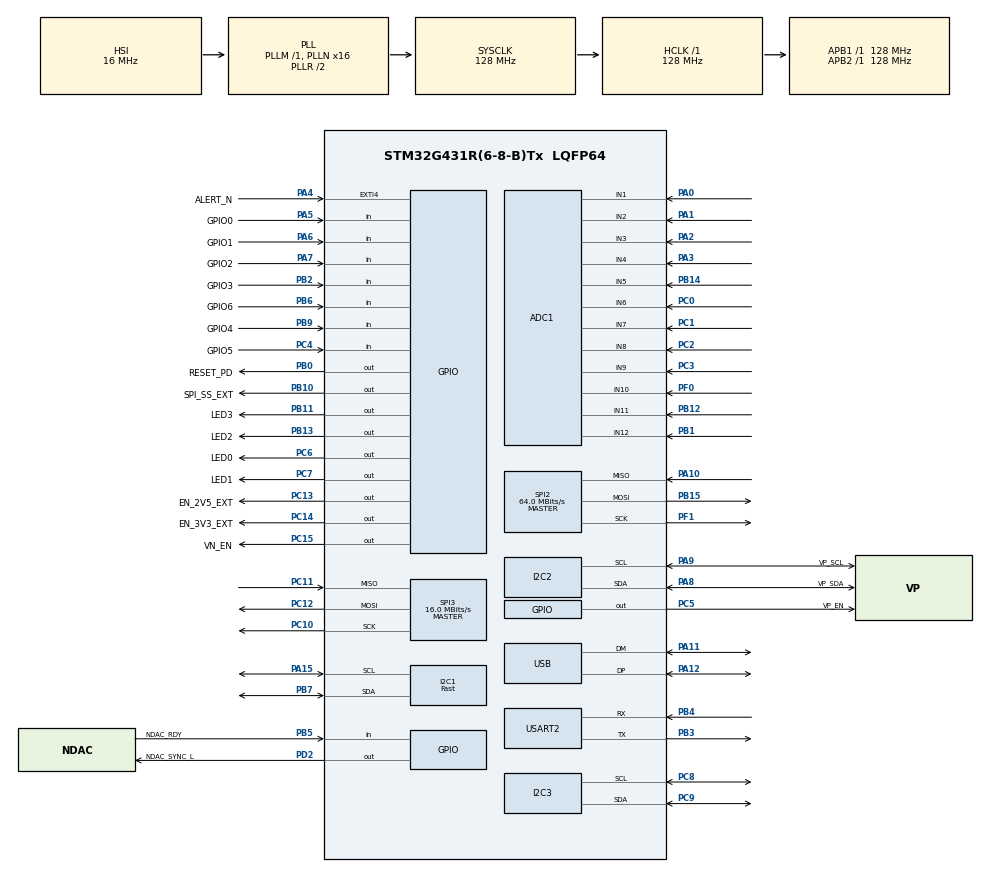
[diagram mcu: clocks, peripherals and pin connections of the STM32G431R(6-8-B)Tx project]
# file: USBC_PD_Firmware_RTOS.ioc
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ADC1.Channel-0\#ChannelRegularConversion=ADC_CHANNEL_1
ADC1.Channel-1\#ChannelRegularConversion=ADC_CHANNEL_2
ADC1.Channel-10\#ChannelRegularConversion=ADC_CHANNEL_12
ADC1.Channel-2\#ChannelRegularConversion=ADC_CHANNEL_4
ADC1.Channel-3\#ChannelRegularConversion=ADC_CHANNEL_5
ADC1.Channel-4\#ChannelRegularConversion=ADC_CHANNEL_6
ADC1.Channel-5\#ChannelRegularConversion=ADC_CHANNEL_7
ADC1.Channel-6\#ChannelRegularConversion=ADC_CHANNEL_8
ADC1.Channel-7\#ChannelRegularConversion=ADC_CHANNEL_9
ADC1.Channel-8\#ChannelRegularConversion=ADC_CHANNEL_10
ADC1.Channel-9\#ChannelRegularConversion=ADC_CHANNEL_11
ADC1.ContinuousConvMode=ENABLE
ADC1.DMAContinuousRequests=ENABLE
ADC1.NbrOfConversion=11
ADC1.NbrOfConversionFlag=1
ADC1.OffsetNumber-0\#ChannelRegularConversion=ADC_OFFSET_NONE
ADC1.OffsetNumber-1\#ChannelRegularConversion=ADC_OFFSET_NONE
ADC1.OffsetNumber-10\#ChannelRegularConversion=ADC_OFFSET_NONE
ADC1.OffsetNumber-2\#ChannelRegularConversion=ADC_OFFSET_NONE
ADC1.OffsetNumber-3\#ChannelRegularConversion=ADC_OFFSET_NONE
ADC1.OffsetNumber-4\#ChannelRegularConversion=ADC_OFFSET_NONE
ADC1.OffsetNumber-5\#ChannelRegularConversion=ADC_OFFSET_NONE
ADC1.OffsetNumber-6\#ChannelRegularConversion=ADC_OFFSET_NONE
ADC1.OffsetNumber-7\#ChannelRegularConversion=ADC_OFFSET_NONE
ADC1.OffsetNumber-8\#ChannelRegularConversion=ADC_OFFSET_NONE
ADC1.OffsetNumber-9\#ChannelRegularConversion=ADC_OFFSET_NONE
ADC1.OversamplingMode=DISABLE
ADC1.Rank-0\#ChannelRegularConversion=1
ADC1.Rank-1\#ChannelRegularConversion=2
ADC1.Rank-10\#ChannelRegularConversion=11
ADC1.Rank-2\#ChannelRegularConversion=3
ADC1.Rank-3\#ChannelRegularConversion=4
ADC1.Rank-4\#ChannelRegularConversion=5
ADC1.Rank-5\#ChannelRegularConversion=6
ADC1.Rank-6\#ChannelRegularConversion=7
ADC1.Rank-7\#ChannelRegularConversion=8
ADC1.Rank-8\#ChannelRegularConversion=9
ADC1.Rank-9\#ChannelRegularConversion=10
ADC1.SamplingTime-0\#ChannelRegularConversion=ADC_SAMPLETIME_12CYCLES_5
ADC1.SamplingTime-1\#ChannelRegularConversion=ADC_SAMPLETIME_12CYCLES_5
ADC1.SamplingTime-10\#ChannelRegularConversion=ADC_SAMPLETIME_12CYCLES_5
ADC1.SamplingTime-2\#ChannelRegularConversion=ADC_SAMPLETIME_12CYCLES_5
ADC1.SamplingTime-3\#ChannelRegularConversion=ADC_SAMPLETIME_12CYCLES_5
ADC1.SamplingTime-4\#ChannelRegularConversion=ADC_SAMPLETIME_12CYCLES_5
ADC1.SamplingTime-5\#ChannelRegularConversion=ADC_SAMPLETIME_12CYCLES_5
ADC1.SamplingTime-6\#ChannelRegularConversion=ADC_SAMPLETIME_12CYCLES_5
ADC1.SamplingTime-7\#ChannelRegularConversion=ADC_SAMPLETIME_12CYCLES_5
ADC1.SamplingTime-8\#ChannelRegularConversion=ADC_SAMPLETIME_12CYCLES_5
ADC1.SamplingTime-9\#ChannelRegularConversion=ADC_SAMPLETIME_12CYCLES_5
ADC1.master=1
Dma.ADC1.0.Direction=DMA_PERIPH_TO_MEMORY
Dma.ADC1.0.EventEnable=DISABLE
Dma.ADC1.0.Instance=DMA1_Channel1
Dma.ADC1.0.MemDataAlignment=DMA_MDATAALIGN_HALFWORD
Dma.ADC1.0.MemInc=DMA_MINC_ENABLE
Dma.ADC1.0.Mode=DMA_CIRCULAR
Dma.ADC1.0.PeriphDataAlignment=DMA_PDATAALIGN_HALFWORD
Dma.ADC1.0.PeriphInc=DMA_PINC_DISABLE
Dma.ADC1.0.Polarity=HAL_DMAMUX_REQ_GEN_RISING
Dma.ADC1.0.Priority=DMA_PRIORITY_LOW
Dma.ADC1.0.RequestNumber=1
Dma.ADC1.0.SignalID=NONE
Dma.ADC1.0.SyncEnable=DISABLE
Dma.ADC1.0.SyncPolarity=HAL_DMAMUX_SYNC_NO_EVENT
Dma.ADC1.0.SyncRequestNumber=1
Dma.ADC1.0.SyncSignalID=NONE
Dma.Request0=ADC1
FREERTOS.Queues01=serialDataQueue,12,uint32_t,0,Dynamic,NULL,NULL
FREERTOS.Tasks01=mainSystemTask,24,128,StartDefaultTask,Default,NULL,Dynamic,NULL,NULL;ledStatusTask,22,128,StartBlinkyTask,Default,NULL,Dynamic,NULL,NULL;usbCommandTask,24,128,StartusbCommandTask,Default,NULL,Dynamic,NULL,NULL;vMeasureTask,23,128,StartvMeasureTask,Default,NULL,Dynamic,NULL,NULL;iMeasureTask,23,128,StartiMeasureTask,Default,NULL,Dynamic,NULL,NULL;cmdResponseTask,25,512,StartResponseTask,Default,NULL,Dynamic,NULL,NULL
FREERTOS.configENABLE_FPU=0
FREERTOS.configTOTAL_HEAP_SIZE=8192
I2C1.I2C_Speed_Mode=I2C_Fast
I2C1.Timing=0x2040184B
I2C2.Timing=0x20A0C4DF
I2C3.Timing=0x20A0C4DF
Mcu.Family=STM32G4
Mcu.Name=STM32G431R(6-8-B)Tx
Mcu.Package=LQFP64
NVIC.DMA1_Channel1_IRQn=true\:5\:0\:false\:false\:true\:true\:false\:true\:true
NVIC.I2C1_EV_IRQn=true\:5\:0\:false\:false\:true\:true\:true\:true\:true
NVIC.PriorityGroup=NVIC_PRIORITYGROUP_4
NVIC.TIM6_DAC_IRQn=true\:15\:0\:false\:false\:true\:false\:false\:true\:true
NVIC.TimeBase=TIM6_DAC_IRQn
NVIC.TimeBaseIP=TIM6
NVIC.USART2_IRQn=true\:5\:0\:false\:false\:true\:true\:true\:true\:true
NVIC.USB_LP_IRQn=true\:5\:0\:false\:false\:true\:true\:false\:true\:true
PA0.Mode=IN1-Single-Ended
PA0.Signal=ADC1_IN1
PA1.Mode=IN2-Single-Ended
PA1.Signal=ADC1_IN2
PA10.Mode=Full_Duplex_Master
PA10.Signal=SPI2_MISO
PA11.Mode=Device
PA11.Signal=USB_DM
PA12.Mode=Device
PA12.Signal=USB_DP
PA13.Mode=Serial_Wire
PA13.Signal=SYS_JTMS-SWDIO
PA14.Mode=Serial_Wire
PA14.Signal=SYS_JTCK-SWCLK
PA15.Mode=I2C
PA15.Signal=I2C1_SCL
PA2.Mode=IN3-Single-Ended
PA2.Signal=ADC1_IN3
PA3.Mode=IN4-Single-Ended
PA3.Signal=ADC1_IN4
PA4.GPIO_Label=ALERT_N
PA4.GPIO_ModeDefaultEXTI=GPIO_MODE_IT_FALLING
PA4.Signal=GPXTI4
PA5.GPIO_Label=GPIO0
PA5.Signal=GPIO_Input
PA6.GPIO_Label=GPIO1
PA6.Signal=GPIO_Input
PA7.GPIO_Label=GPIO2
PA7.Signal=GPIO_Input
PA8.GPIO_Label=VP_SDA
PA8.Mode=I2C
PA8.Signal=I2C2_SDA
PA9.GPIO_Label=VP_SCL
PA9.Mode=I2C
PA9.Signal=I2C2_SCL
PB0.GPIO_Label=RESET_PD
PB0.Signal=GPIO_Output
PB1.Mode=IN12-Single-Ended
PB1.Signal=ADC1_IN12
PB10.GPIO_Label=SPI_SS_EXT
PB10.Signal=GPIO_Output
PB11.GPIO_Label=LED3
PB11.PinState=GPIO_PIN_SET
PB11.Signal=GPIO_Output
PB12.Mode=IN11-Single-Ended
PB12.Signal=ADC1_IN11
PB13.GPIO_Label=LED2
PB13.PinState=GPIO_PIN_SET
PB13.Signal=GPIO_Output
PB14.Mode=IN5-Single-Ended
PB14.Signal=ADC1_IN5
PB15.Mode=Full_Duplex_Master
PB15.Signal=SPI2_MOSI
PB2.GPIO_Label=GPIO3
PB2.Signal=GPIO_Input
PB3.Mode=Asynchronous
PB3.Signal=USART2_TX
PB4.Mode=Asynchronous
PB4.Signal=USART2_RX
PB5.GPIO_Label=NDAC_RDY
PB5.Signal=GPIO_Input
PB6.GPIO_Label=GPIO6
PB6.Signal=GPIO_Input
PB7.Mode=I2C
PB7.Signal=I2C1_SDA
PB9.GPIO_Label=GPIO4
PB9.Signal=GPIO_Input
PC0.Mode=IN6-Single-Ended
PC0.Signal=ADC1_IN6
PC1.Mode=IN7-Single-Ended
PC1.Signal=ADC1_IN7
PC10.Mode=Full_Duplex_Master
PC10.Signal=SPI3_SCK
PC11.Mode=Full_Duplex_Master
PC11.Signal=SPI3_MISO
PC12.Mode=Full_Duplex_Master
PC12.Signal=SPI3_MOSI
PC13.GPIO_Label=EN_2V5_EXT
PC13.GPIO_ModeDefaultOutputPP=GPIO_MODE_OUTPUT_OD
PC13.GPIO_PuPd=GPIO_NOPULL
PC13.PinState=GPIO_PIN_SET
PC13.Signal=GPIO_Output
PC14-OSC32_IN.GPIO_Label=EN_3V3_EXT
PC14-OSC32_IN.GPIO_ModeDefaultOutputPP=GPIO_MODE_OUTPUT_OD
PC14-OSC32_IN.GPIO_PuPd=GPIO_NOPULL
PC14-OSC32_IN.PinState=GPIO_PIN_SET
PC14-OSC32_IN.Signal=GPIO_Output
PC15-OSC32_OUT.GPIO_Label=VN_EN
PC15-OSC32_OUT.Signal=GPIO_Output
PC2.Mode=IN8-Single-Ended
PC2.Signal=ADC1_IN8
PC3.Mode=IN9-Single-Ended
PC3.Signal=ADC1_IN9
PC4.GPIO_Label=GPIO5
PC4.Signal=GPIO_Input
PC5.GPIO_Label=VP_EN
PC5.Signal=GPIO_Output
PC6.GPIO_Label=LED0
PC6.PinState=GPIO_PIN_SET
PC6.Signal=GPIO_Output
PC7.GPIO_Label=LED1
PC7.PinState=GPIO_PIN_SET
PC7.Signal=GPIO_Output
PC8.Mode=I2C
PC8.Signal=I2C3_SCL
PC9.Mode=I2C
PC9.Signal=I2C3_SDA
PD2.GPIO_Label=NDAC_SYNC_L
PD2.PinState=GPIO_PIN_SET
PD2.Signal=GPIO_Output
PF0-OSC_IN.Mode=IN10-Single-Ended
PF0-OSC_IN.Signal=ADC1_IN10
PF1-OSC_OUT.Mode=Full_Duplex_Master
PF1-OSC_OUT.Signal=SPI2_SCK
ProjectManager.HeapSize=0x200
ProjectManager.StackSize=0x400
ProjectManager.TargetToolchain=STM32CubeIDE
RCC.ADC12Freq_Value=128000000
RCC.AHBFreq_Value=128000000
RCC.APB1Freq_Value=128000000
RCC.APB1TimFreq_Value=128000000
RCC.APB2Freq_Value=128000000
RCC.APB2TimFreq_Value=128000000
RCC.CK48CLockSelection=RCC_USBCLKSOURCE_HSI48
RCC.CortexFreq_Value=128000000
RCC.EXTERNAL_CLOCK_VALUE=12288000
RCC.HCLKFreq_Value=128000000
RCC.HSE_VALUE=8000000
RCC.HSI48_VALUE=48000000
RCC.HSI_VALUE=16000000
RCC.LSE_VALUE=32768
RCC.PLLN=16
RCC.PLLQ=RCC_PLLQ_DIV4
RCC.SYSCLKFreq_VALUE=128000000
RCC.SYSCLKSource=RCC_SYSCLKSOURCE_PLLCLK
RCC.USBFreq_Value=48000000
RCC.VCOOutputFreq_Value=256000000
SPI2.CalculateBaudRate=64.0 MBits/s
SPI2.Direction=SPI_DIRECTION_2LINES
SPI2.Mode=SPI_MODE_MASTER
SPI2.VirtualType=VM_MASTER
SPI3.BaudRatePrescaler=SPI_BAUDRATEPRESCALER_8
SPI3.CLKPhase=SPI_PHASE_2EDGE
SPI3.CalculateBaudRate=16.0 MBits/s
SPI3.DataSize=SPI_DATASIZE_16BIT
SPI3.Direction=SPI_DIRECTION_2LINES
SPI3.Mode=SPI_MODE_MASTER
SPI3.VirtualType=VM_MASTER
USART2.VirtualMode-Asynchronous=VM_ASYNC
USB_DEVICE.CLASS_NAME_FS=CDC
USB_DEVICE.VirtualMode=Cdc
USB_DEVICE.VirtualModeFS=Cdc_FS
VP_FREERTOS_VS_CMSIS_V2.Mode=CMSIS_V2
VP_SYS_VS_DBSignals.Mode=DisableDeadBatterySignals
VP_SYS_VS_tim6.Mode=TIM6
VP_USB_DEVICE_VS_USB_DEVICE_CDC_FS.Mode=CDC_FS
board=custom

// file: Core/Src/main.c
/* USER CODE BEGIN Header */
/**
  ******************************************************************************
  * @file           : main.c
  * @brief          : Main program body
  ******************************************************************************
  * @attention
  *
  * Copyright (c) 2026 STMicroelectronics.
  * All rights reserved.
  *
  * This software is licensed under terms that can be found in the LICENSE file
  * in the root directory of this software component.
  * If no LICENSE file comes with this software, it is provided AS-IS.
  *
  ******************************************************************************
  */
/* USER CODE END Header */
#include "main.h"
#include "cmsis_os.h"
#include "usb_device.h"

/* USER CODE BEGIN Includes */
#include "System_Functions.h"
#include "USB_PD_core.h"
#include "usb_cmd.h"
#include "System_RTOS.h"
/* USER CODE END Includes */

ADC_HandleTypeDef hadc1;
DMA_HandleTypeDef hdma_adc1;

I2C_HandleTypeDef hi2c1;
I2C_HandleTypeDef hi2c2;
I2C_HandleTypeDef hi2c3;

SPI_HandleTypeDef hspi2;
SPI_HandleTypeDef hspi3;

UART_HandleTypeDef huart2;

/* Definitions for mainSystemTask */
osThreadId_t mainSystemTaskHandle;
const osThreadAttr_t mainSystemTask_attributes = {
  .name = "mainSystemTask",
  .priority = (osPriority_t) osPriorityNormal,
//  .stack_size = 128 * 4
  .stack_size = 280
};
/* Definitions for ledStatusTask */
osThreadId_t ledStatusTaskHandle;
const osThreadAttr_t ledStatusTask_attributes = {
  .name = "ledStatusTask",
  .priority = (osPriority_t) osPriorityBelowNormal6,
//  .stack_size = 128 * 4
  .stack_size = 224
};
/* Definitions for usbCommandTask */
osThreadId_t usbCommandTaskHandle;
const osThreadAttr_t usbCommandTask_attributes = {
  .name = "usbCommandTask",
  .priority = (osPriority_t) osPriorityNormal,
//  .stack_size = 512 * 4
  .stack_size = 1024
};
/* Definitions for vMeasureTask */
osThreadId_t vMeasureTaskHandle;
const osThreadAttr_t vMeasureTask_attributes = {
  .name = "vMeasureTask",
  .priority = (osPriority_t) osPriorityBelowNormal7,
//  .stack_size = 128 * 4
  .stack_size = 192
};
/* Definitions for iMeasureTask */
osThreadId_t iMeasureTaskHandle;
const osThreadAttr_t iMeasureTask_attributes = {
  .name = "iMeasureTask",
  .priority = (osPriority_t) osPriorityBelowNormal7,
//  .stack_size = 128 * 4
  .stack_size = 512
};
/* Definitions for cmdResponseTask */
osThreadId_t cmdResponseTaskHandle;
const osThreadAttr_t cmdResponseTask_attributes = {
  .name = "cmdResponseTask",
  .priority = (osPriority_t) osPriorityNormal1,
//  .stack_size = 512 * 4
  .stack_size = 1024
};
/* Definitions for serialDataQueue */
osMessageQueueId_t serialDataQueueHandle;
const osMessageQueueAttr_t serialDataQueue_attributes = {
  .name = "serialDataQueue"
};

void SystemClock_Config(void);
static void MX_GPIO_Init(void);
static void MX_DMA_Init(void);
static void MX_ADC1_Init(void);
static void MX_I2C1_Init(void);
static void MX_I2C2_Init(void);
static void MX_USART2_UART_Init(void);
static void MX_I2C3_Init(void);
static void MX_SPI2_Init(void);
static void MX_SPI3_Init(void);

int main(void)
{

  /* MCU Configuration--------------------------------------------------------*/

  /* Reset of all peripherals, Initializes the Flash interface and the Systick. */
  HAL_Init();

  /* Configure the system clock */
  SystemClock_Config();

  /* Initialize all configured peripherals */
  MX_GPIO_Init();
  MX_DMA_Init();
  MX_ADC1_Init();
  MX_I2C1_Init();
  MX_I2C2_Init();
  MX_USART2_UART_Init();
  MX_I2C3_Init();
  MX_SPI2_Init();
  MX_SPI3_Init();

  /* Init scheduler */
  osKernelInitialize();

  /* Create the queue(s) */
  /* creation of serialDataQueue */
  serialDataQueueHandle = osMessageQueueNew (12, sizeof(SerialMsg_t), &serialDataQueue_attributes);

  /* Create the thread(s) */
  /* creation of mainSystemTask */
  mainSystemTaskHandle = osThreadNew(StartDefaultTask, NULL, &mainSystemTask_attributes);

  /* creation of ledStatusTask */
  ledStatusTaskHandle = osThreadNew(StartBlinkyTask, NULL, &ledStatusTask_attributes);

  /* creation of usbCommandTask */
  usbCommandTaskHandle = osThreadNew(StartusbCommandTask, NULL, &usbCommandTask_attributes);

  /* creation of vMeasureTask */
  vMeasureTaskHandle = osThreadNew(StartvMeasureTask, NULL, &vMeasureTask_attributes);

  /* creation of iMeasureTask */
  iMeasureTaskHandle = osThreadNew(StartiMeasureTask, NULL, &iMeasureTask_attributes);

  /* creation of cmdResponseTask */
  cmdResponseTaskHandle = osThreadNew(StartResponseTask, NULL, &cmdResponseTask_attributes);

  /* Start scheduler */
  osKernelStart();

  /* We should never get here as control is now taken by the scheduler */

  /* Infinite loop */
  while (1)
  {

  }
}

void SystemClock_Config(void)
{
  RCC_OscInitTypeDef RCC_OscInitStruct = {0};
  RCC_ClkInitTypeDef RCC_ClkInitStruct = {0};

  /** Configure the main internal regulator output voltage
  */
  HAL_PWREx_ControlVoltageScaling(PWR_REGULATOR_VOLTAGE_SCALE1);

  /** Initializes the RCC Oscillators according to the specified parameters
  * in the RCC_OscInitTypeDef structure.
  */
  RCC_OscInitStruct.OscillatorType = RCC_OSCILLATORTYPE_HSI|RCC_OSCILLATORTYPE_HSI48;
  RCC_OscInitStruct.HSIState = RCC_HSI_ON;
  RCC_OscInitStruct.HSICalibrationValue = RCC_HSICALIBRATION_DEFAULT;
  RCC_OscInitStruct.HSI48State = RCC_HSI48_ON;
  RCC_OscInitStruct.PLL.PLLState = RCC_PLL_ON;
  RCC_OscInitStruct.PLL.PLLSource = RCC_PLLSOURCE_HSI;
  RCC_OscInitStruct.PLL.PLLM = RCC_PLLM_DIV1;
  RCC_OscInitStruct.PLL.PLLN = 16;
  RCC_OscInitStruct.PLL.PLLP = RCC_PLLP_DIV2;
  RCC_OscInitStruct.PLL.PLLQ = RCC_PLLQ_DIV4;
  RCC_OscInitStruct.PLL.PLLR = RCC_PLLR_DIV2;
  if (HAL_RCC_OscConfig(&RCC_OscInitStruct) != HAL_OK)
  {
    Error_Handler();
  }

  /** Initializes the CPU, AHB and APB buses clocks
  */
  RCC_ClkInitStruct.ClockType = RCC_CLOCKTYPE_HCLK|RCC_CLOCKTYPE_SYSCLK
                              |RCC_CLOCKTYPE_PCLK1|RCC_CLOCKTYPE_PCLK2;
  RCC_ClkInitStruct.SYSCLKSource = RCC_SYSCLKSOURCE_PLLCLK;
  RCC_ClkInitStruct.AHBCLKDivider = RCC_SYSCLK_DIV1;
  RCC_ClkInitStruct.APB1CLKDivider = RCC_HCLK_DIV1;
  RCC_ClkInitStruct.APB2CLKDivider = RCC_HCLK_DIV1;

  if (HAL_RCC_ClockConfig(&RCC_ClkInitStruct, FLASH_LATENCY_4) != HAL_OK)
  {
    Error_Handler();
  }
}

static void MX_ADC1_Init(void)
{

  ADC_MultiModeTypeDef multimode = {0};
  ADC_ChannelConfTypeDef sConfig = {0};

  /** Common config
  */
  hadc1.Instance = ADC1;
  hadc1.Init.ClockPrescaler = ADC_CLOCK_ASYNC_DIV128;
  hadc1.Init.Resolution = ADC_RESOLUTION_12B;
  hadc1.Init.DataAlign = ADC_DATAALIGN_RIGHT;
  hadc1.Init.GainCompensation = 0;
  hadc1.Init.ScanConvMode = ADC_SCAN_ENABLE;
  hadc1.Init.EOCSelection = ADC_EOC_SINGLE_CONV;
  hadc1.Init.LowPowerAutoWait = DISABLE;
  hadc1.Init.ContinuousConvMode = ENABLE;
  hadc1.Init.NbrOfConversion = 11;
  hadc1.Init.DiscontinuousConvMode = DISABLE;
  hadc1.Init.ExternalTrigConv = ADC_SOFTWARE_START;
  hadc1.Init.ExternalTrigConvEdge = ADC_EXTERNALTRIGCONVEDGE_NONE;
  hadc1.Init.DMAContinuousRequests = ENABLE;
  hadc1.Init.Overrun = ADC_OVR_DATA_PRESERVED;
  hadc1.Init.OversamplingMode = DISABLE;
  if (HAL_ADC_Init(&hadc1) != HAL_OK)
  {
    Error_Handler();
  }

  /** Configure the ADC multi-mode
  */
  multimode.Mode = ADC_MODE_INDEPENDENT;
  if (HAL_ADCEx_MultiModeConfigChannel(&hadc1, &multimode) != HAL_OK)
  {
    Error_Handler();
  }

  /** Configure Regular Channel
  */
  sConfig.Channel = ADC_CHANNEL_1;
  sConfig.Rank = ADC_REGULAR_RANK_1;
  sConfig.SamplingTime = ADC_SAMPLETIME_92CYCLES_5;
  sConfig.SingleDiff = ADC_SINGLE_ENDED;
  sConfig.OffsetNumber = ADC_OFFSET_NONE;
  sConfig.Offset = 0;
  if (HAL_ADC_ConfigChannel(&hadc1, &sConfig) != HAL_OK)
  {
    Error_Handler();
  }

  /** Configure Regular Channel
  */
  sConfig.Channel = ADC_CHANNEL_2;
  sConfig.Rank = ADC_REGULAR_RANK_2;
  if (HAL_ADC_ConfigChannel(&hadc1, &sConfig) != HAL_OK)
  {
    Error_Handler();
  }

  /** Configure Regular Channel
  */
  sConfig.Channel = ADC_CHANNEL_4;
  sConfig.Rank = ADC_REGULAR_RANK_3;
  if (HAL_ADC_ConfigChannel(&hadc1, &sConfig) != HAL_OK)
  {
    Error_Handler();
  }

  /** Configure Regular Channel
  */
  sConfig.Channel = ADC_CHANNEL_5;
  sConfig.Rank = ADC_REGULAR_RANK_4;
  if (HAL_ADC_ConfigChannel(&hadc1, &sConfig) != HAL_OK)
  {
    Error_Handler();
  }

  /** Configure Regular Channel
  */
  sConfig.Channel = ADC_CHANNEL_6;
  sConfig.Rank = ADC_REGULAR_RANK_5;
  if (HAL_ADC_ConfigChannel(&hadc1, &sConfig) != HAL_OK)
  {
    Error_Handler();
  }

  /** Configure Regular Channel
  */
  sConfig.Channel = ADC_CHANNEL_7;
  sConfig.Rank = ADC_REGULAR_RANK_6;
  if (HAL_ADC_ConfigChannel(&hadc1, &sConfig) != HAL_OK)
  {
    Error_Handler();
  }

  /** Configure Regular Channel
  */
  sConfig.Channel = ADC_CHANNEL_8;
  sConfig.Rank = ADC_REGULAR_RANK_7;
  if (HAL_ADC_ConfigChannel(&hadc1, &sConfig) != HAL_OK)
  {
    Error_Handler();
  }

  /** Configure Regular Channel
  */
  sConfig.Channel = ADC_CHANNEL_9;
  sConfig.Rank = ADC_REGULAR_RANK_8;
  if (HAL_ADC_ConfigChannel(&hadc1, &sConfig) != HAL_OK)
  {
    Error_Handler();
  }

  /** Configure Regular Channel
  */
  sConfig.Channel = ADC_CHANNEL_10;
  sConfig.Rank = ADC_REGULAR_RANK_9;
  if (HAL_ADC_ConfigChannel(&hadc1, &sConfig) != HAL_OK)
  {
    Error_Handler();
  }

  /** Configure Regular Channel
  */
  sConfig.Channel = ADC_CHANNEL_11;
  sConfig.Rank = ADC_REGULAR_RANK_10;
  if (HAL_ADC_ConfigChannel(&hadc1, &sConfig) != HAL_OK)
  {
    Error_Handler();
  }

  /** Configure Regular Channel
  */
  sConfig.Channel = ADC_CHANNEL_12;
  sConfig.Rank = ADC_REGULAR_RANK_11;
  if (HAL_ADC_ConfigChannel(&hadc1, &sConfig) != HAL_OK)
  {
    Error_Handler();
  }

}

static void MX_I2C1_Init(void)
{

  hi2c1.Instance = I2C1;
  hi2c1.Init.Timing = 0x2040184B;
  hi2c1.Init.OwnAddress1 = 0;
  hi2c1.Init.AddressingMode = I2C_ADDRESSINGMODE_7BIT;
  hi2c1.Init.DualAddressMode = I2C_DUALADDRESS_DISABLE;
  hi2c1.Init.OwnAddress2 = 0;
  hi2c1.Init.OwnAddress2Masks = I2C_OA2_NOMASK;
  hi2c1.Init.GeneralCallMode = I2C_GENERALCALL_DISABLE;
  hi2c1.Init.NoStretchMode = I2C_NOSTRETCH_DISABLE;
  if (HAL_I2C_Init(&hi2c1) != HAL_OK)
  {
    Error_Handler();
  }

  /** Configure Analogue filter
  */
  if (HAL_I2CEx_ConfigAnalogFilter(&hi2c1, I2C_ANALOGFILTER_ENABLE) != HAL_OK)
  {
    Error_Handler();
  }

  /** Configure Digital filter
  */
  if (HAL_I2CEx_ConfigDigitalFilter(&hi2c1, 0) != HAL_OK)
  {
    Error_Handler();
  }

}

static void MX_I2C2_Init(void)
{

  hi2c2.Instance = I2C2;
  hi2c2.Init.Timing = 0x20A0C4DF;
  hi2c2.Init.OwnAddress1 = 0;
  hi2c2.Init.AddressingMode = I2C_ADDRESSINGMODE_7BIT;
  hi2c2.Init.DualAddressMode = I2C_DUALADDRESS_DISABLE;
  hi2c2.Init.OwnAddress2 = 0;
  hi2c2.Init.OwnAddress2Masks = I2C_OA2_NOMASK;
  hi2c2.Init.GeneralCallMode = I2C_GENERALCALL_DISABLE;
  hi2c2.Init.NoStretchMode = I2C_NOSTRETCH_DISABLE;
  if (HAL_I2C_Init(&hi2c2) != HAL_OK)
  {
    Error_Handler();
  }

  /** Configure Analogue filter
  */
  if (HAL_I2CEx_ConfigAnalogFilter(&hi2c2, I2C_ANALOGFILTER_ENABLE) != HAL_OK)
  {
    Error_Handler();
  }

  /** Configure Digital filter
  */
  if (HAL_I2CEx_ConfigDigitalFilter(&hi2c2, 0) != HAL_OK)
  {
    Error_Handler();
  }

}

static void MX_I2C3_Init(void)
{

  hi2c3.Instance = I2C3;
  hi2c3.Init.Timing = 0x20A0C4DF;
  hi2c3.Init.OwnAddress1 = 0;
  hi2c3.Init.AddressingMode = I2C_ADDRESSINGMODE_7BIT;
  hi2c3.Init.DualAddressMode = I2C_DUALADDRESS_DISABLE;
  hi2c3.Init.OwnAddress2 = 0;
  hi2c3.Init.OwnAddress2Masks = I2C_OA2_NOMASK;
  hi2c3.Init.GeneralCallMode = I2C_GENERALCALL_DISABLE;
  hi2c3.Init.NoStretchMode = I2C_NOSTRETCH_DISABLE;
  if (HAL_I2C_Init(&hi2c3) != HAL_OK)
  {
    Error_Handler();
  }

  /** Configure Analogue filter
  */
  if (HAL_I2CEx_ConfigAnalogFilter(&hi2c3, I2C_ANALOGFILTER_ENABLE) != HAL_OK)
  {
    Error_Handler();
  }

  /** Configure Digital filter
  */
  if (HAL_I2CEx_ConfigDigitalFilter(&hi2c3, 0) != HAL_OK)
  {
    Error_Handler();
  }

}

static void MX_SPI2_Init(void)
{

  /* SPI2 parameter configuration*/
  hspi2.Instance = SPI2;
  hspi2.Init.Mode = SPI_MODE_MASTER;
  hspi2.Init.Direction = SPI_DIRECTION_2LINES;
  hspi2.Init.DataSize = SPI_DATASIZE_4BIT;
  hspi2.Init.CLKPolarity = SPI_POLARITY_LOW;
  hspi2.Init.CLKPhase = SPI_PHASE_1EDGE;
  hspi2.Init.NSS = SPI_NSS_SOFT;
  hspi2.Init.BaudRatePrescaler = SPI_BAUDRATEPRESCALER_2;
  hspi2.Init.FirstBit = SPI_FIRSTBIT_MSB;
  hspi2.Init.TIMode = SPI_TIMODE_DISABLE;
  hspi2.Init.CRCCalculation = SPI_CRCCALCULATION_DISABLE;
  hspi2.Init.CRCPolynomial = 7;
  hspi2.Init.CRCLength = SPI_CRC_LENGTH_DATASIZE;
  hspi2.Init.NSSPMode = SPI_NSS_PULSE_ENABLE;
  if (HAL_SPI_Init(&hspi2) != HAL_OK)
  {
    Error_Handler();
  }

}

static void MX_SPI3_Init(void)
{

  /* SPI3 parameter configuration*/
  hspi3.Instance = SPI3;
  hspi3.Init.Mode = SPI_MODE_MASTER;
  hspi3.Init.Direction = SPI_DIRECTION_2LINES;
  hspi3.Init.DataSize = SPI_DATASIZE_16BIT;
  hspi3.Init.CLKPolarity = SPI_POLARITY_LOW;
  hspi3.Init.CLKPhase = SPI_PHASE_2EDGE;
  hspi3.Init.NSS = SPI_NSS_SOFT;
  hspi3.Init.BaudRatePrescaler = SPI_BAUDRATEPRESCALER_8;
  hspi3.Init.FirstBit = SPI_FIRSTBIT_MSB;
  hspi3.Init.TIMode = SPI_TIMODE_DISABLE;
  hspi3.Init.CRCCalculation = SPI_CRCCALCULATION_DISABLE;
  hspi3.Init.CRCPolynomial = 7;
  hspi3.Init.CRCLength = SPI_CRC_LENGTH_DATASIZE;
  hspi3.Init.NSSPMode = SPI_NSS_PULSE_DISABLE;
  if (HAL_SPI_Init(&hspi3) != HAL_OK)
  {
    Error_Handler();
  }

}

static void MX_USART2_UART_Init(void)
{

  huart2.Instance = USART2;
  huart2.Init.BaudRate = 115200;
  huart2.Init.WordLength = UART_WORDLENGTH_8B;
  huart2.Init.StopBits = UART_STOPBITS_1;
  huart2.Init.Parity = UART_PARITY_NONE;
  huart2.Init.Mode = UART_MODE_TX_RX;
  huart2.Init.HwFlowCtl = UART_HWCONTROL_NONE;
  huart2.Init.OverSampling = UART_OVERSAMPLING_16;
  huart2.Init.OneBitSampling = UART_ONE_BIT_SAMPLE_DISABLE;
  huart2.Init.ClockPrescaler = UART_PRESCALER_DIV1;
  huart2.AdvancedInit.AdvFeatureInit = UART_ADVFEATURE_NO_INIT;
  if (HAL_UART_Init(&huart2) != HAL_OK)
  {
    Error_Handler();
  }
  if (HAL_UARTEx_SetTxFifoThreshold(&huart2, UART_TXFIFO_THRESHOLD_1_8) != HAL_OK)
  {
    Error_Handler();
  }
  if (HAL_UARTEx_SetRxFifoThreshold(&huart2, UART_RXFIFO_THRESHOLD_1_8) != HAL_OK)
  {
    Error_Handler();
  }
  if (HAL_UARTEx_DisableFifoMode(&huart2) != HAL_OK)
  {
    Error_Handler();
  }

}

static void MX_DMA_Init(void)
{

  /* DMA controller clock enable */
  __HAL_RCC_DMAMUX1_CLK_ENABLE();
  __HAL_RCC_DMA1_CLK_ENABLE();

  /* DMA interrupt init */
  /* DMA1_Channel1_IRQn interrupt configuration */
  HAL_NVIC_SetPriority(DMA1_Channel1_IRQn, 5, 0);
  HAL_NVIC_EnableIRQ(DMA1_Channel1_IRQn);

}

static void MX_GPIO_Init(void)
{
  GPIO_InitTypeDef GPIO_InitStruct = {0};

  /* GPIO Ports Clock Enable */
  __HAL_RCC_GPIOC_CLK_ENABLE();
  __HAL_RCC_GPIOF_CLK_ENABLE();
  __HAL_RCC_GPIOA_CLK_ENABLE();
  __HAL_RCC_GPIOB_CLK_ENABLE();
  __HAL_RCC_GPIOD_CLK_ENABLE();

  /*Configure GPIO pin Output Level */
  HAL_GPIO_WritePin(GPIOC, EN_2V5_EXT_Pin|EN_3V3_EXT_Pin|LED0_Pin|LED1_Pin, GPIO_PIN_SET);

  /*Configure GPIO pin Output Level */
  HAL_GPIO_WritePin(GPIOC, VN_EN_Pin|VP_EN_Pin, GPIO_PIN_RESET);

  /*Configure GPIO pin Output Level */
  HAL_GPIO_WritePin(GPIOB, RESET_PD_Pin|SPI_SS_EXT_Pin, GPIO_PIN_RESET);

  /*Configure GPIO pin Output Level */
  HAL_GPIO_WritePin(GPIOB, LED3_Pin|LED2_Pin, GPIO_PIN_SET);

  /*Configure GPIO pin Output Level */
  HAL_GPIO_WritePin(NDAC_SYNC_L_GPIO_Port, NDAC_SYNC_L_Pin, GPIO_PIN_SET);

  /*Configure GPIO pins : EN_2V5_EXT_Pin EN_3V3_EXT_Pin */
  GPIO_InitStruct.Pin = EN_2V5_EXT_Pin|EN_3V3_EXT_Pin;
  GPIO_InitStruct.Mode = GPIO_MODE_OUTPUT_OD;
  GPIO_InitStruct.Pull = GPIO_NOPULL;
  GPIO_InitStruct.Speed = GPIO_SPEED_FREQ_LOW;
  HAL_GPIO_Init(GPIOC, &GPIO_InitStruct);

  /*Configure GPIO pins : VN_EN_Pin VP_EN_Pin LED0_Pin LED1_Pin */
  GPIO_InitStruct.Pin = VN_EN_Pin|VP_EN_Pin|LED0_Pin|LED1_Pin;
  GPIO_InitStruct.Mode = GPIO_MODE_OUTPUT_PP;
  GPIO_InitStruct.Pull = GPIO_NOPULL;
  GPIO_InitStruct.Speed = GPIO_SPEED_FREQ_LOW;
  HAL_GPIO_Init(GPIOC, &GPIO_InitStruct);

  /*Configure GPIO pin : ALERT_N_Pin */
  GPIO_InitStruct.Pin = ALERT_N_Pin;
  GPIO_InitStruct.Mode = GPIO_MODE_IT_FALLING;
  GPIO_InitStruct.Pull = GPIO_NOPULL;
  HAL_GPIO_Init(ALERT_N_GPIO_Port, &GPIO_InitStruct);

  /*Configure GPIO pins : GPIO0_Pin GPIO1_Pin GPIO2_Pin */
  GPIO_InitStruct.Pin = GPIO0_Pin|GPIO1_Pin|GPIO2_Pin;
  GPIO_InitStruct.Mode = GPIO_MODE_INPUT;
  GPIO_InitStruct.Pull = GPIO_NOPULL;
  HAL_GPIO_Init(GPIOA, &GPIO_InitStruct);

  /*Configure GPIO pin : GPIO5_Pin */
  GPIO_InitStruct.Pin = GPIO5_Pin;
  GPIO_InitStruct.Mode = GPIO_MODE_INPUT;
  GPIO_InitStruct.Pull = GPIO_NOPULL;
  HAL_GPIO_Init(GPIO5_GPIO_Port, &GPIO_InitStruct);

  /*Configure GPIO pins : RESET_PD_Pin SPI_SS_EXT_Pin LED3_Pin LED2_Pin GPIO6_Pin */
  GPIO_InitStruct.Pin = RESET_PD_Pin|SPI_SS_EXT_Pin|LED3_Pin|LED2_Pin|GPIO6_Pin;
  GPIO_InitStruct.Mode = GPIO_MODE_OUTPUT_PP;
  GPIO_InitStruct.Pull = GPIO_NOPULL;
  GPIO_InitStruct.Speed = GPIO_SPEED_FREQ_LOW;
  HAL_GPIO_Init(GPIOB, &GPIO_InitStruct);

  /*Configure GPIO pins : GPIO3_Pin NDAC_RDY_Pin GPIO4_Pin */
  GPIO_InitStruct.Pin = GPIO3_Pin|NDAC_RDY_Pin|GPIO4_Pin;
  GPIO_InitStruct.Mode = GPIO_MODE_INPUT;
  GPIO_InitStruct.Pull = GPIO_NOPULL;
  HAL_GPIO_Init(GPIOB, &GPIO_InitStruct);

  /*Configure GPIO pin : NDAC_SYNC_L_Pin */
  GPIO_InitStruct.Pin = NDAC_SYNC_L_Pin;
  GPIO_InitStruct.Mode = GPIO_MODE_OUTPUT_PP;
  GPIO_InitStruct.Pull = GPIO_NOPULL;
  GPIO_InitStruct.Speed = GPIO_SPEED_FREQ_LOW;
  HAL_GPIO_Init(NDAC_SYNC_L_GPIO_Port, &GPIO_InitStruct);

}

void HAL_TIM_PeriodElapsedCallback(TIM_HandleTypeDef *htim)
{
  if (htim->Instance == TIM6) {
    HAL_IncTick();
  }
}

void Error_Handler(void)
{
  __disable_irq();
  while (1)
  {
  }
}
